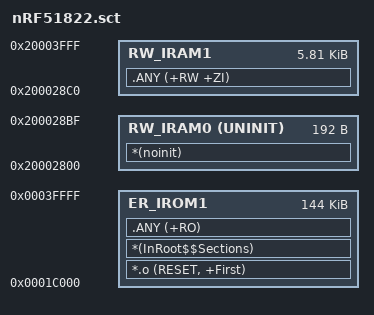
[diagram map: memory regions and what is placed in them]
;WITHOUT SOFTDEVICE:
;LR_IROM1 0x00000000 0x00040000  {
;  ER_IROM1 0x00000000 0x00040000  {
;   *.o (RESET, +First)
;   *(InRoot$$Sections)
;   .ANY (+RO)
;  }
;  RW_IRAM1 0x20000000 0x00004000  {
;   .ANY (+RW +ZI)
;  }
;}
;
;WITH SOFTDEVICE:

LR_IROM1 0x1C000 0x0024000  {
  ER_IROM1 0x1C000 0x0024000  {
   *.o (RESET, +First)
   *(InRoot$$Sections)
   .ANY (+RO)
  }
  RW_IRAM0 0x20002800 UNINIT 0x000000c0  { ;no init section
        *(noinit)
  }
  RW_IRAM1 0x200028C0 0x00001740  {
   .ANY (+RW +ZI)
  }
}
